# cslr_lcdc_001 register map
Vendor: Texas Instruments
Peripheral module from a debugger description file (folder C5515).
Address unit: 16 bits
Registers are 16-bit, read-write, reset 0x0 unless marked. A register's access mark holds for its fields unless they carry their own. Offsets are as the file gives them; lines under a group give offsets from that group; [hi:lo] are bit positions; {n}, {i} and the like mark numbered series; 'fields as' and 'values as' point back to an identical list; <NAME> marks a mode.

## LCDC — LCD Controller
0x00 LCDREVMIN reset 0x1000 — LCD Minor Revision Register
  [15:0] REVMIN — Minor Revision
0x01 LCDREVMAJ reset not defined — LCD Major Revision Register
  [15:0] REVMAJ — Major Revision
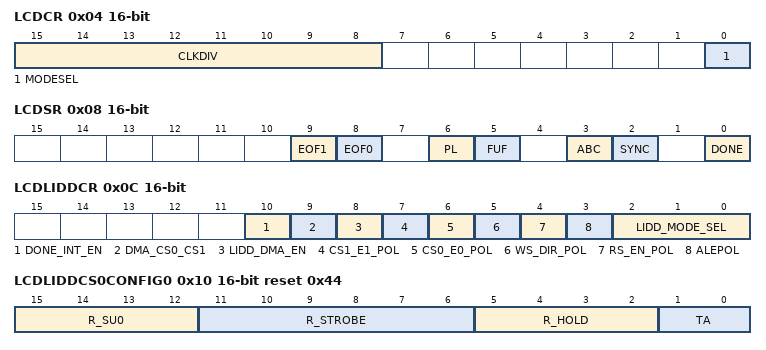
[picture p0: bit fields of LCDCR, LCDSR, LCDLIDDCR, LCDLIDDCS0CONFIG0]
0x04 LCDCR access not given — LCD Control Register
  [15:8] CLKDIV rw — Clock Divisor Value (from 0 255) is used to specify the frequency of the pixel clock (in Raster mode) or MCLK (in LIDD mode) based on the lcd_clk frequency. Pixel clock frequency can range from lcd_clk/2 to lcd_clk/255 (clkdiv=0 or clkdiv=1 are N/A); MCLK can vary from lcd_clk to lcd_clk/255 (clkdiv=0 or clkdiv=1 sets MCLK=lcd_clk)
  [0] MODESEL rw — LCD Mode Select
    0=LIDD (LCD Controller in LIDD mode); 1=RASTER (LCD Controller in Raster mode)
0x08 LCDSR access not given — LCD Status Register
  [9] EOF1 rw — End of Frame 1 0: no end of frame 1 detected 1: end of frame 1 detected
    0=CLEAR (End of frame 1 not detected); 1=SET (end of frame 1 detected)
  [8] EOF0 rw — End of Frame 0 0: no end of frame 0 detected 1: end of frame 0 detected
    0=CLEAR (End of frame 0 not detected); 1=SET (end of frame 0 detected)
  [6] PL rw — Loaded Palette 0: The palette is not loaded 1: The palette is loaded
    0=CLEAR (Palette not loaded); 1=SET (Palette loaded)
  [5] FUF rw — FIFO Underflow Status 0: FIFO has not underrun 1: LCD dither logic not supplying data to FIFO at a sufficient rate, FIFO has completely emptied and data pin driver logic has attempted to take added data from FIFO
    0=CLEAR (No FIFO underrun); 1=SET (FIFO completely empty and data pin attempted to take added data from FIFO)
  [3] ABC rw — AC Bias Count Status 0: AC bias transition counter has not decremented to zero 1: AC bias transition counter has decremented to zero, indicating that the lcd_ac_o line has transitioned the number of times which is specified by the acbi control bit-field. Counter is reloaded with value in acbi but is disabled until the user clears ABC
    0=CLEAR (AC bias transition counter not zero); 1=SET (AC bias transition counter decremented to zero)
  [2] SYNC rw — Sync Lost 0: normal 1: Frame Synchronization Lost has occurred
    0=CLEAR (Normal operation); 1=SET (Lost Frame Sync)
  [0] DONE rw — Raster or LIDD Frame Done (shared; depends on whether Raster or LIDD mode enabled) 0: Raster or DMA-to-LIDD engine is enabled 1: Raster or DMA-to-LIDD disabled and the active frame has just completed
    0=CLEAR (Raster engine enabled); 1=SET (Raster engine disabled)
0x0C LCDLIDDCR access not given — LCD LIDD Control Register
  [10] DONE_INT_EN rw — LIDD Frame Done Interrupt Enable 0: Disable LIDD Frame Done interrupt 1: Enable LIDD Frame Done interrupt (seen on LCD Status Reg bit 0)
    0=DISABLE (Disable LIDD Frame Done interrupt); 1=ENABLE (Enable LIDD Frame Done interrupt (seen on LCD Status Reg bit 0))
  [9] DMA_CS0_CS1 rw — CS0/CS1 Select for LIDD DMA writes 0: DMA writes to LIDD CS0 1: DMA writes to LIDD CS1
    0=CS0 (DMA writes to LIDD CS0); 1=CS1 (DMA writes to LIDD CS1)
  [8] LIDD_DMA_EN rw — LIDD DMA Enable 0: Deactivate DMA control of LIDD interface; DMA control is released upon completion of transfer of the currentframe of data (LIDD Frame Done) after this bit is cleared. The MPU has direct read/write access to the panel in this mode 1: Activate DMA to drive LIDD interface to support streaming data to smart panels. The MPU cannot access the panel directly in this mode
    0=DISABLE (Disable DMA control of LIDD); 1=ENABLE (Enable DMA to drive LIDD interface to support streaming data to smart panels.)
  [7] CS1_E1_POL rw — Chip Select 1/Enable 1 (Secondary) Polarity Control 0: Do Not Invert Chip Select 1/Enable 1 1: Invert Chip Select 1/Enable 1 Chip Select 1 is active low by default; Enable 1 is active high by default
    0=NORMAL (No Invert for CS1/EN1); 1=INVERT (Inverts CS1/EN1)
  [6] CS0_E0_POL rw — Chip Select 0/Enable 0 (Primary) Polarity Control 0: Do Not Invert Chip Select 0/Enable 0 1: Invert Chip Select 0/Enable 0 Chip Select 0 is active low by default; Enable 0 is active high by default
    0=NORMAL (No Invert for CS0/EN0); 1=INVERT (Inverts CS0/EN0)
  [5] WS_DIR_POL rw — Write Strobe/Direction Polarity Control 0: Do Not Invert Write Strobe/Direction 1: Invert Write Strobe/Direction Write Strobe/Direction is active low/write low by default
    0=NORMAL (No Invert for WS/Dir); 1=INVERT (Invert WS/Dir)
  [4] RS_EN_POL rw — Read Strobe/Enable Polarity Control 0: Do Not Invert Read Strobe/Enable 1: Invert Read Strobe/Enable Read Strobe is active low by default; Enable is active high by default
    0=NORMAL (No invert for RS/En); 1=INVERT (Invert RS/En)
  [3] ALEPOL rw — Address Latch Enable (ALE) Polarity Control 0: Do Not Invert ALE 1: Invert ALE ALE is active low by default
    0=NORMAL (No invert for ALE); 1=INVERT (Invert ALE)
  [2:0] LIDD_MODE_SEL rw — LIDD Mode Select. Selects type of LCD display interface for the LIDD to drive LIDD Mode Select defines the function of LCD external pins as follows ------------------------------------------------------------------------------------ PIN 000b 001b 010b 011b 100b ------------------------------------------------------------------------------------ lcd_cp En En Rs Rs N/A lcd_lp Dir Dir Ws Ws Dir lcd_fp Ale Ale Ale Ale Ale lcd_ac Cs0 Cs0 Cs0 Cs0 E0 lcd_mclk Mclk Cs1 Mclk Cs1 E1
    0=SYNC_MPU68; 1=ASYNC_MPU68; 2=SYNC_MPU80; 3=ASYNC_MPU80; 4=HITACHI (Hitachi (Async))
0x10 LCDLIDDCS0CONFIG0 reset 0x44 — LCD LIDD CS0 Configuration Register 0
  [15:12] R_SU0 — Read Strobe Set-Up cycles (lower 4 bits upper bit is in LIDD CSO config reg 1 at bit-0) Field value defines number of memclk cycles after Data Bus/Pad Output Enable, ALE, Direction bit and Chip Select 0 have been set-up before the Read Strobe is asserted when performing a read access
  [11:6] R_STROBE — Read Strobe Duration cycles Field value defines number of memclk cycles for which the Read Strobe is held active when performing a read access
  [5:2] R_HOLD — Read Strobe Hold cycles Field value defines number of memclk cycles for which Data Bus/Pad Output Enable, ALE, Direction bit and Chip Select 0 are held after the Read Strobe is deasserted when performing a read access
  [1:0] TA — Field value defines number of memclk cycles between the end of one CS0 device access and the start of another CS0 device access unless the two accesses are both reads, in which case this delay is not incurred
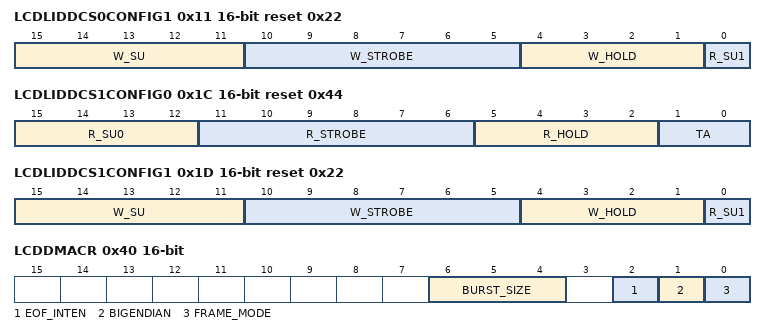
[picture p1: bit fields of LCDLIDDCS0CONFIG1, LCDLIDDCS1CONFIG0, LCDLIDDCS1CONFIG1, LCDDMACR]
0x11 LCDLIDDCS0CONFIG1 reset 0x22 — LCD LIDD CS0 Configuration Register 1
  [15:11] W_SU — Write Strobe Set-Up cycles Field value defines number of memclk cycles after Data Bus/Pad Output Enable, ALE, Direction bit and Chip Select 0 have been set-up before the Write Strobe is asserted when performing a write access
  [10:5] W_STROBE — Write Strobe Duration cycles Field value defines number of memclk cycles for which the Write Strobe is held active when performing a write access
  [4:1] W_HOLD — Write Strobe Hold cycles Field value defines number of memclk cycles for which Data Bus/Pad Output Enable, ALE, Direction bit and Chip Select 0 are held after the Write Strobe is deasserted when performing a write access
  [0] R_SU1 — Most Significant Bit for Read Strobe Set-Up cycles (upper bit. The lower 4 bits are located in LIDD CSO confir reg 0) Field value defines number of memclk cycles after Data Bus/Pad Output Enable, ALE, Direction bit and Chip Select 0 have been set-up before the Read Strobe is asserted when performing a read access
0x14 LCDLIDDCS0ADDR — LCD LIDD CS0 Address Read/Write Register
  [15:0] ADR_INDX — Peripheral Device Address/Index value On writes this field is loaded into the CS0 peripheral device s address generator On reads this field contains the CS0 peripheral device s status
0x18 LCDLIDDCS0DATA — LCD LIDD CS0 Data Read/Write Register
  [15:0] DATA — Peripheral Device Data value On writes this field is loaded into the CS0 peripheral device On reads this field contains the CS0 peripheral device s data
0x1C LCDLIDDCS1CONFIG0 reset 0x44 — LCD LIDD CS1 Configuration Register 0
  fields as LCDLIDDCS0CONFIG0
0x1D LCDLIDDCS1CONFIG1 reset 0x22 — LCD LIDD CS1 Configuration Register 1
  [15:11] W_SU — Write Strobe Set-Up cycles Field value defines number of memclk cycles after Data Bus/Pad Output Enable, ALE, Direction bit and Chip Select 0 have been set-up before the Write Strobe is asserted when performing a write access
  [10:5] W_STROBE — Write Strobe Duration cycles Field value defines number of memclk cycles for which the Write Strobe is held active when performing a write access
  [4:1] W_HOLD — Write Strobe Hold cycles Field value defines number of memclk cycles for which Data Bus/Pad Output Enable, ALE, Direction bit and Chip Select 0 are held after the Write Strobe is deasserted when performing a write access
  [0] R_SU1 — Read Strobe Set-Up cycles (upper bit. The lower 4 bits are located in LIDD CSO confir reg 0) Field value defines number of memclk cycles after Data Bus/Pad Output Enable, ALE, Direction bit and Chip Select 0 have been set-up before the Read Strobe is asserted when performing a read access
0x20 LCDLIDDCS1ADDR — LCD LIDD CS1 Address Read/Write Register
  fields as LCDLIDDCS0ADDR
0x24 LCDLIDDCS1DATA — LCD LIDD CS1 Data Read/Write Register
  fields as LCDLIDDCS0DATA
0x40 LCDDMACR access not given — LCD DMA Control Register
  [6:4] BURST_SIZE rw — Burst Size setting for DMA transfers (all DMA transfers are 32 bits wide)
    0=BSIZE1 (burst size of 1); 1=BSIZE2 (burst size of 2); 2=BSIZE4 (burst size of 4); 3=BSIZE8 (burst size of 8); 4=BSIZE16 (burst size of 16)
  [2] EOF_INTEN rw — End of Frame interrupt enable Setting this bit allows the End of Frame 0 or 1 Status bits in the LCD Status Register to trigger an interrupt 0: End of Frame 0/1Interrupt disabled 1: End of Frame 0/1Interrupt enabled
    0=DISABLED (EoF Interrupt disabled); 1=ENABLED (EoF Interrupt enabled)
  [1] BIGENDIAN rw — Big Endian enable Use this bit when the processor is operating in Big Endian mode and writes to the frame buffer(s) are less than 32 bits wide; only in this scenario we need to change the byte alignment for data coming into the FIFO from the frame buffer(s) 0: Big Endian data reordering disabled 1: Big Endian data reordering enabled
    0=DISABLED (Big Endian disabled); 1=ENABLED (Big Endian enabled)
  [0] FRAME_MODE rw — Frame Mode 0: one frame buffer (FB0 only) used 1: two frame buffers used; DMA ping-pongs between FB0 and FB1 in this mode
    0=ONE (One Frame buffer used); 1=TWO (two frame buffers used.)
0x44 LCDDMAFB0BAR0 — LCD DMA Frame Buffer 0 Base Address Register 0
  [15:0] FB0_BASE0 — Frame Buffer 0 Base Address pointer LSW; 2 LSBs are hardwired to be 00
0x45 LCDDMAFB0BAR1 — LCD DMA Frame Buffer 0 Base Address Register 1
  [15:0] FB0_BASE1 — Frame Buffer 0 Base Address pointer MSW
0x48 LCDDMAFB0CAR0 — LCD DMA Frame Buffer 0 Ceiling Address Register 0
  [15:0] FB0_CEIL0 — Frame Buffer 0 Ceiling Address pointer LSW; 2 LSBs are hardwired to be 00
0x49 LCDDMAFB0CAR1 — LCD DMA Frame Buffer 0 Ceiling Address Register 1
  [15:0] FB0_CEIL1 — Frame Buffer 0 Ceiling Address pointer MSW
0x4C LCDDMAFB1BAR0 — LCD DMA Frame Buffer 1 Base Address Register 0
  [15:0] FB1_BASE0 — Frame Buffer 1 Base Address pointer LSW; 2 LSBs are hardwired to be 00
0x4D LCDDMAFB1BAR1 — LCD DMA Frame Buffer 1 Base Address Register 1
  [15:0] FB1_BASE1 — Frame Buffer 1 Base Address pointer MSW
0x50 LCDDMAFB1CAR0 — LCD DMA Frame Buffer 1 Ceiling Address Register 0
  [15:0] FB1_CEIL0 — Frame Buffer 1 Ceiling Address pointer LSW; 2 LSBs are hardwired to be 00
0x51 LCDDMAFB1CAR1 — LCD DMA Frame Buffer 1 Ceiling Address Register 1
  [15:0] FB1_CEIL1 — Frame Buffer 1 Ceiling Address pointer MSW
